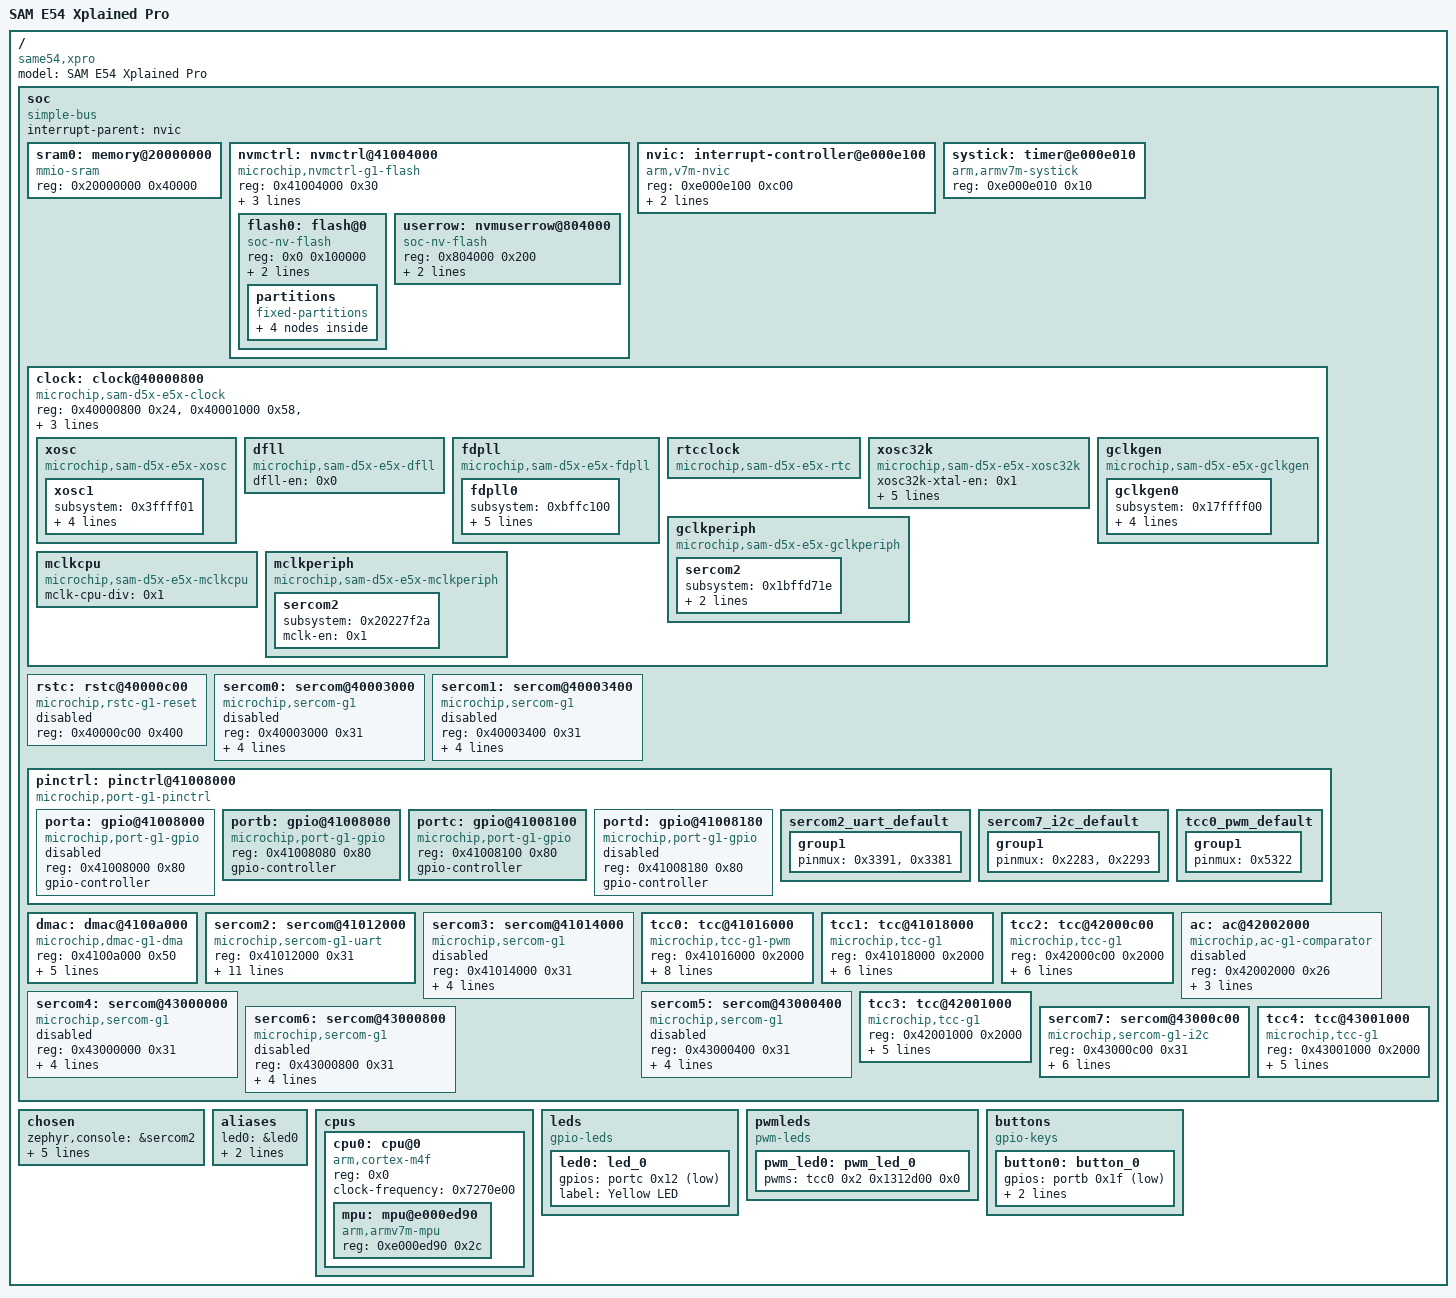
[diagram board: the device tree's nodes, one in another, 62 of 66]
/dts-v1/;

/* node '/' defined in zephyr/dts/arm/microchip/sam/sam_d5x_e5x/common/samd5xe5x_20.dtsi:7 */
/ {
	#address-cells = < 0x1 >;              /* in zephyr/dts/common/skeleton.dtsi:10 */
	#size-cells = < 0x1 >;                 /* in zephyr/dts/common/skeleton.dtsi:11 */
	model = "SAM E54 Xplained Pro";        /* in zephyr/boards/microchip/sam/sam_e54_xpro/sam_e54_xpro.dts:14 */
	compatible = "same54,xpro",
	             "microchip,atsame54p20a",
	             "microchip,same54";       /* in zephyr/boards/microchip/sam/sam_e54_xpro/sam_e54_xpro.dts:15 */

	/* node '/soc' defined in zephyr/dts/arm/microchip/sam/sam_d5x_e5x/common/samd5xe5x_20.dtsi:8 */
	soc {
		#address-cells = < 0x1 >;     /* in zephyr/dts/arm/armv7-m.dtsi:7 */
		#size-cells = < 0x1 >;        /* in zephyr/dts/arm/armv7-m.dtsi:8 */
		compatible = "simple-bus";    /* in zephyr/dts/arm/armv7-m.dtsi:9 */
		interrupt-parent = < &nvic >; /* in zephyr/dts/arm/armv7-m.dtsi:10 */
		ranges;                       /* in zephyr/dts/arm/armv7-m.dtsi:11 */

		/* node '/soc/memory@20000000' defined in zephyr/dts/arm/microchip/sam/sam_d5x_e5x/common/samd5xe5x_20.dtsi:9 */
		sram0: memory@20000000 {
			reg = < 0x20000000 0x40000 >; /* in zephyr/dts/arm/microchip/sam/sam_d5x_e5x/common/samd5xe5x_20.dtsi:10 */
			compatible = "mmio-sram";     /* in zephyr/dts/arm/microchip/sam/sam_d5x_e5x/common/samd5xe5x.dtsi:33 */
		};

		/* node '/soc/nvmctrl@41004000' defined in zephyr/dts/arm/microchip/sam/sam_d5x_e5x/common/samd5xe5x_20.dtsi:13 */
		nvmctrl: nvmctrl@41004000 {
			compatible = "microchip,nvmctrl-g1-flash"; /* in zephyr/dts/arm/microchip/sam/sam_d5x_e5x/common/samd5xe5x.dtsi:115 */
			status = "okay";                           /* in zephyr/dts/arm/microchip/sam/sam_d5x_e5x/common/samd5xe5x.dtsi:116 */
			reg = < 0x41004000 0x30 >;                 /* in zephyr/dts/arm/microchip/sam/sam_d5x_e5x/common/samd5xe5x.dtsi:117 */
			interrupts = < 0x1d 0x0 >,
			             < 0x1e 0x0 >;                 /* in zephyr/dts/arm/microchip/sam/sam_d5x_e5x/common/samd5xe5x.dtsi:118 */
			clocks = < &mclkperiph 0x2020bf27 >;       /* in zephyr/dts/arm/microchip/sam/sam_d5x_e5x/common/samd5xe5x.dtsi:119 */
			clock-names = "mclk";                      /* in zephyr/dts/arm/microchip/sam/sam_d5x_e5x/common/samd5xe5x.dtsi:120 */
			lock-regions = < 0x20 >;                   /* in zephyr/dts/arm/microchip/sam/sam_d5x_e5x/common/samd5xe5x.dtsi:121 */
			#address-cells = < 0x1 >;                  /* in zephyr/dts/arm/microchip/sam/sam_d5x_e5x/common/samd5xe5x.dtsi:122 */
			#size-cells = < 0x1 >;                     /* in zephyr/dts/arm/microchip/sam/sam_d5x_e5x/common/samd5xe5x.dtsi:123 */

			/* node '/soc/nvmctrl@41004000/flash@0' defined in zephyr/dts/arm/microchip/sam/sam_d5x_e5x/common/samd5xe5x_20.dtsi:14 */
			flash0: flash@0 {
				reg = < 0x0 0x100000 >;        /* in zephyr/dts/arm/microchip/sam/sam_d5x_e5x/common/samd5xe5x_20.dtsi:15 */
				compatible = "soc-nv-flash";   /* in zephyr/dts/arm/microchip/sam/sam_d5x_e5x/common/samd5xe5x.dtsi:126 */
				write-block-size = < 0x8 >;    /* in zephyr/dts/arm/microchip/sam/sam_d5x_e5x/common/samd5xe5x.dtsi:127 */
				erase-block-size = < 0x2000 >; /* in zephyr/dts/arm/microchip/sam/sam_d5x_e5x/common/samd5xe5x.dtsi:128 */

				/* node '/soc/nvmctrl@41004000/flash@0/partitions' defined in zephyr/boards/microchip/sam/sam_e54_xpro/sam_e54_xpro.dts:62 */
				partitions {
					compatible = "fixed-partitions"; /* in zephyr/boards/microchip/sam/sam_e54_xpro/sam_e54_xpro.dts:63 */
					#address-cells = < 0x1 >;        /* in zephyr/boards/microchip/sam/sam_e54_xpro/sam_e54_xpro.dts:64 */
					#size-cells = < 0x1 >;           /* in zephyr/boards/microchip/sam/sam_e54_xpro/sam_e54_xpro.dts:65 */

					/* node '/soc/nvmctrl@41004000/flash@0/partitions/partition@0' defined in zephyr/boards/microchip/sam/sam_e54_xpro/sam_e54_xpro.dts:67 */
					boot_partition: partition@0 {
						reg = < 0x0 0x10000 >; /* in zephyr/boards/microchip/sam/sam_e54_xpro/sam_e54_xpro.dts:68 */
						read-only;             /* in zephyr/boards/microchip/sam/sam_e54_xpro/sam_e54_xpro.dts:69 */
					};

					/* node '/soc/nvmctrl@41004000/flash@0/partitions/partition@10000' defined in zephyr/boards/microchip/sam/sam_e54_xpro/sam_e54_xpro.dts:72 */
					slot0_partition: partition@10000 {
						reg = < 0x10000 0x70000 >; /* in zephyr/boards/microchip/sam/sam_e54_xpro/sam_e54_xpro.dts:73 */
					};

					/* node '/soc/nvmctrl@41004000/flash@0/partitions/partition@80000' defined in zephyr/boards/microchip/sam/sam_e54_xpro/sam_e54_xpro.dts:76 */
					slot1_partition: partition@80000 {
						reg = < 0x80000 0x70000 >; /* in zephyr/boards/microchip/sam/sam_e54_xpro/sam_e54_xpro.dts:77 */
					};

					/* node '/soc/nvmctrl@41004000/flash@0/partitions/partition@f0000' defined in zephyr/boards/microchip/sam/sam_e54_xpro/sam_e54_xpro.dts:80 */
					storage_partition: partition@f0000 {
						reg = < 0xf0000 0x10000 >; /* in zephyr/boards/microchip/sam/sam_e54_xpro/sam_e54_xpro.dts:81 */
					};
				};
			};

			/* node '/soc/nvmctrl@41004000/nvmuserrow@804000' defined in zephyr/dts/arm/microchip/sam/sam_d5x_e5x/common/samd5xe5x.dtsi:131 */
			userrow: nvmuserrow@804000 {
				compatible = "soc-nv-flash";  /* in zephyr/dts/arm/microchip/sam/sam_d5x_e5x/common/samd5xe5x.dtsi:132 */
				reg = < 0x804000 0x200 >;     /* in zephyr/dts/arm/microchip/sam/sam_d5x_e5x/common/samd5xe5x.dtsi:133 */
				write-block-size = < 0x8 >;   /* in zephyr/dts/arm/microchip/sam/sam_d5x_e5x/common/samd5xe5x.dtsi:134 */
				erase-block-size = < 0x200 >; /* in zephyr/dts/arm/microchip/sam/sam_d5x_e5x/common/samd5xe5x.dtsi:135 */
			};
		};

		/* node '/soc/interrupt-controller@e000e100' defined in zephyr/dts/arm/armv7-m.dtsi:13 */
		nvic: interrupt-controller@e000e100 {
			#address-cells = < 0x1 >;            /* in zephyr/dts/arm/armv7-m.dtsi:14 */
			compatible = "arm,v7m-nvic";         /* in zephyr/dts/arm/armv7-m.dtsi:15 */
			reg = < 0xe000e100 0xc00 >;          /* in zephyr/dts/arm/armv7-m.dtsi:16 */
			interrupt-controller;                /* in zephyr/dts/arm/armv7-m.dtsi:17 */
			#interrupt-cells = < 0x2 >;          /* in zephyr/dts/arm/armv7-m.dtsi:18 */
			arm,num-irq-priority-bits = < 0x3 >; /* in zephyr/dts/arm/microchip/sam/sam_d5x_e5x/common/samd5xe5x.dtsi:261 */
			phandle = < 0x1 >;                   /* in zephyr/dts/arm/armv7-m.dtsi:10 */
		};

		/* node '/soc/timer@e000e010' defined in zephyr/dts/arm/armv7-m.dtsi:21 */
		systick: timer@e000e010 {
			compatible = "arm,armv7m-systick"; /* in zephyr/dts/arm/armv7-m.dtsi:22 */
			reg = < 0xe000e010 0x10 >;         /* in zephyr/dts/arm/armv7-m.dtsi:23 */
		};

		/* node '/soc/clock@40000800' defined in zephyr/dts/arm/microchip/sam/sam_d5x_e5x/common/samd5xe5x.dtsi:36 */
		clock: clock@40000800 {
			reg = < 0x40000800 0x24 >,
			      < 0x40001000 0x58 >,
			      < 0x40001400 0x20 >,
			      < 0x40001c00 0x140 >;                 /* in zephyr/dts/arm/microchip/sam/sam_d5x_e5x/common/samd5xe5x.dtsi:38 */
			reg-names = "mclk",
			            "oscctrl",
			            "osc32kctrl",
			            "gclk";                         /* in zephyr/dts/arm/microchip/sam/sam_d5x_e5x/common/samd5xe5x.dtsi:40 */
			interrupts = < 0x1 0x0 >,
			             < 0x2 0x0 >,
			             < 0x3 0x0 >,
			             < 0x4 0x0 >,
			             < 0x5 0x0 >,
			             < 0x6 0x0 >,
			             < 0x7 0x0 >;                   /* in zephyr/dts/arm/microchip/sam/sam_d5x_e5x/common/samd5xe5x.dtsi:42 */
			interrupt-names = "mclk",
			                  "xosc0",
			                  "xosc1",
			                  "dfll",
			                  "fdpll0",
			                  "fdpll1",
			                  "xosc32k";                /* in zephyr/dts/arm/microchip/sam/sam_d5x_e5x/common/samd5xe5x.dtsi:44 */
			compatible = "microchip,sam-d5x-e5x-clock"; /* in zephyr/boards/microchip/sam/sam_e54_xpro/sam_e54_xpro.dts:91 */

			/* node '/soc/clock@40000800/xosc' defined in zephyr/dts/arm/microchip/sam/sam_d5x_e5x/common/samd5xe5x.dtsi:47 */
			xosc: xosc {
				compatible = "microchip,sam-d5x-e5x-xosc"; /* in zephyr/boards/microchip/sam/sam_e54_xpro/sam_e54_xpro.dts:94 */

				/* node '/soc/clock@40000800/xosc/xosc1' defined in zephyr/boards/microchip/sam/sam_e54_xpro/sam_e54_xpro.dts:96 */
				xosc1 {
					subsystem = < 0x3ffff01 >;        /* in zephyr/boards/microchip/sam/sam_e54_xpro/sam_e54_xpro.dts:97 */
					xosc-frequency = < 0xb71b00 >;    /* in zephyr/boards/microchip/sam/sam_e54_xpro/sam_e54_xpro.dts:98 */
					xosc-en = < 0x1 >;                /* in zephyr/boards/microchip/sam/sam_e54_xpro/sam_e54_xpro.dts:99 */
					xosc-xtal-en = < 0x1 >;           /* in zephyr/boards/microchip/sam/sam_e54_xpro/sam_e54_xpro.dts:100 */
					xosc-run-in-standby-en = < 0x1 >; /* in zephyr/boards/microchip/sam/sam_e54_xpro/sam_e54_xpro.dts:101 */
				};
			};

			/* node '/soc/clock@40000800/dfll' defined in zephyr/dts/arm/microchip/sam/sam_d5x_e5x/common/samd5xe5x.dtsi:51 */
			dfll: dfll {
				compatible = "microchip,sam-d5x-e5x-dfll"; /* in zephyr/boards/microchip/sam/sam_e54_xpro/sam_e54_xpro.dts:106 */
				dfll-en = < 0x0 >;                         /* in zephyr/boards/microchip/sam/sam_e54_xpro/sam_e54_xpro.dts:107 */
			};

			/* node '/soc/clock@40000800/fdpll' defined in zephyr/dts/arm/microchip/sam/sam_d5x_e5x/common/samd5xe5x.dtsi:55 */
			fdpll: fdpll {
				compatible = "microchip,sam-d5x-e5x-fdpll"; /* in zephyr/boards/microchip/sam/sam_e54_xpro/sam_e54_xpro.dts:111 */

				/* node '/soc/clock@40000800/fdpll/fdpll0' defined in zephyr/boards/microchip/sam/sam_e54_xpro/sam_e54_xpro.dts:113 */
				fdpll0 {
					subsystem = < 0xbffc100 >;          /* in zephyr/boards/microchip/sam/sam_e54_xpro/sam_e54_xpro.dts:114 */
					fdpll-divider-ratio-int = < 0x13 >; /* in zephyr/boards/microchip/sam/sam_e54_xpro/sam_e54_xpro.dts:115 */
					fdpll-lock-bypass-en = < 0x1 >;     /* in zephyr/boards/microchip/sam/sam_e54_xpro/sam_e54_xpro.dts:116 */
					fdpll-wakeup-fast-en = < 0x1 >;     /* in zephyr/boards/microchip/sam/sam_e54_xpro/sam_e54_xpro.dts:117 */
					fdpll-src = "xosc1";                /* in zephyr/boards/microchip/sam/sam_e54_xpro/sam_e54_xpro.dts:118 */
					fdpll-en = < 0x1 >;                 /* in zephyr/boards/microchip/sam/sam_e54_xpro/sam_e54_xpro.dts:119 */
				};
			};

			/* node '/soc/clock@40000800/rtcclock' defined in zephyr/dts/arm/microchip/sam/sam_d5x_e5x/common/samd5xe5x.dtsi:59 */
			rtcclock: rtcclock {
				compatible = "microchip,sam-d5x-e5x-rtc"; /* in zephyr/dts/arm/microchip/sam/sam_d5x_e5x/common/samd5xe5x.dtsi:60 */
				#clock-cells = < 0x1 >;                   /* in zephyr/dts/arm/microchip/sam/sam_d5x_e5x/common/samd5xe5x.dtsi:61 */
			};

			/* node '/soc/clock@40000800/xosc32k' defined in zephyr/dts/arm/microchip/sam/sam_d5x_e5x/common/samd5xe5x.dtsi:64 */
			xosc32k: xosc32k {
				compatible = "microchip,sam-d5x-e5x-xosc32k"; /* in zephyr/boards/microchip/sam/sam_e54_xpro/sam_e54_xpro.dts:124 */
				xosc32k-xtal-en = < 0x1 >;                    /* in zephyr/boards/microchip/sam/sam_e54_xpro/sam_e54_xpro.dts:125 */
				xosc32k-startup-time = < 0x3e >;              /* in zephyr/boards/microchip/sam/sam_e54_xpro/sam_e54_xpro.dts:126 */
				xosc32k-gain-mode = "standard";               /* in zephyr/boards/microchip/sam/sam_e54_xpro/sam_e54_xpro.dts:127 */
				xosc32k-en = < 0x1 >;                         /* in zephyr/boards/microchip/sam/sam_e54_xpro/sam_e54_xpro.dts:128 */
				xosc32k-32khz-en = < 0x1 >;                   /* in zephyr/boards/microchip/sam/sam_e54_xpro/sam_e54_xpro.dts:129 */
				xosc32k-1khz-en = < 0x1 >;                    /* in zephyr/boards/microchip/sam/sam_e54_xpro/sam_e54_xpro.dts:130 */
			};

			/* node '/soc/clock@40000800/gclkgen' defined in zephyr/dts/arm/microchip/sam/sam_d5x_e5x/common/samd5xe5x.dtsi:68 */
			gclkgen: gclkgen {
				compatible = "microchip,sam-d5x-e5x-gclkgen"; /* in zephyr/boards/microchip/sam/sam_e54_xpro/sam_e54_xpro.dts:134 */

				/* node '/soc/clock@40000800/gclkgen/gclkgen0' defined in zephyr/boards/microchip/sam/sam_e54_xpro/sam_e54_xpro.dts:136 */
				gclkgen0 {
					subsystem = < 0x17ffff00 >;          /* in zephyr/boards/microchip/sam/sam_e54_xpro/sam_e54_xpro.dts:137 */
					gclkgen-div-factor = < 0x1 >;        /* in zephyr/boards/microchip/sam/sam_e54_xpro/sam_e54_xpro.dts:138 */
					gclkgen-run-in-standby-en = < 0x1 >; /* in zephyr/boards/microchip/sam/sam_e54_xpro/sam_e54_xpro.dts:139 */
					gclkgen-src = "fdpll0";              /* in zephyr/boards/microchip/sam/sam_e54_xpro/sam_e54_xpro.dts:140 */
					gclkgen-en = < 0x1 >;                /* in zephyr/boards/microchip/sam/sam_e54_xpro/sam_e54_xpro.dts:141 */
				};
			};

			/* node '/soc/clock@40000800/gclkperiph' defined in zephyr/dts/arm/microchip/sam/sam_d5x_e5x/common/samd5xe5x.dtsi:72 */
			gclkperiph: gclkperiph {
				compatible = "microchip,sam-d5x-e5x-gclkperiph"; /* in zephyr/boards/microchip/sam/sam_e54_xpro/sam_e54_xpro.dts:146 */
				#clock-cells = < 0x1 >;                          /* in zephyr/boards/microchip/sam/sam_e54_xpro/sam_e54_xpro.dts:147 */
				phandle = < 0x3 >;                               /* in zephyr/dts/arm/microchip/sam/sam_d5x_e5x/common/samd5xe5x.dtsi:99 */

				/* node '/soc/clock@40000800/gclkperiph/sercom2' defined in zephyr/boards/microchip/sam/sam_e54_xpro/sam_e54_xpro.dts:149 */
				sercom2 {
					subsystem = < 0x1bffd71e >; /* in zephyr/boards/microchip/sam/sam_e54_xpro/sam_e54_xpro.dts:150 */
					gclkperiph-src = "gclk0";   /* in zephyr/boards/microchip/sam/sam_e54_xpro/sam_e54_xpro.dts:151 */
					gclkperiph-en = < 0x1 >;    /* in zephyr/boards/microchip/sam/sam_e54_xpro/sam_e54_xpro.dts:152 */
				};
			};

			/* node '/soc/clock@40000800/mclkcpu' defined in zephyr/dts/arm/microchip/sam/sam_d5x_e5x/common/samd5xe5x.dtsi:77 */
			mclkcpu: mclkcpu {
				compatible = "microchip,sam-d5x-e5x-mclkcpu"; /* in zephyr/dts/arm/microchip/sam/sam_d5x_e5x/common/samd5xe5x.dtsi:78 */
				mclk-cpu-div = < 0x1 >;                       /* in zephyr/dts/arm/microchip/sam/sam_d5x_e5x/common/samd5xe5x.dtsi:79 */
			};

			/* node '/soc/clock@40000800/mclkperiph' defined in zephyr/dts/arm/microchip/sam/sam_d5x_e5x/common/samd5xe5x.dtsi:82 */
			mclkperiph: mclkperiph {
				compatible = "microchip,sam-d5x-e5x-mclkperiph"; /* in zephyr/boards/microchip/sam/sam_e54_xpro/sam_e54_xpro.dts:157 */
				#clock-cells = < 0x1 >;                          /* in zephyr/boards/microchip/sam/sam_e54_xpro/sam_e54_xpro.dts:158 */
				phandle = < 0x2 >;                               /* in zephyr/dts/arm/microchip/sam/sam_d5x_e5x/common/samd5xe5x.dtsi:119 */

				/* node '/soc/clock@40000800/mclkperiph/sercom2' defined in zephyr/boards/microchip/sam/sam_e54_xpro/sam_e54_xpro.dts:160 */
				sercom2 {
					subsystem = < 0x20227f2a >; /* in zephyr/boards/microchip/sam/sam_e54_xpro/sam_e54_xpro.dts:161 */
					mclk-en = < 0x1 >;          /* in zephyr/boards/microchip/sam/sam_e54_xpro/sam_e54_xpro.dts:162 */
				};
			};
		};

		/* node '/soc/rstc@40000c00' defined in zephyr/dts/arm/microchip/sam/sam_d5x_e5x/common/samd5xe5x.dtsi:88 */
		rstc: rstc@40000c00 {
			compatible = "microchip,rstc-g1-reset"; /* in zephyr/dts/arm/microchip/sam/sam_d5x_e5x/common/samd5xe5x.dtsi:89 */
			status = "disabled";                    /* in zephyr/dts/arm/microchip/sam/sam_d5x_e5x/common/samd5xe5x.dtsi:90 */
			reg = < 0x40000c00 0x400 >;             /* in zephyr/dts/arm/microchip/sam/sam_d5x_e5x/common/samd5xe5x.dtsi:91 */
		};

		/* node '/soc/sercom@40003000' defined in zephyr/dts/arm/microchip/sam/sam_d5x_e5x/common/samd5xe5x.dtsi:94 */
		sercom0: sercom@40003000 {
			compatible = "microchip,sercom-g1";  /* in zephyr/dts/arm/microchip/sam/sam_d5x_e5x/common/samd5xe5x.dtsi:95 */
			status = "disabled";                 /* in zephyr/dts/arm/microchip/sam/sam_d5x_e5x/common/samd5xe5x.dtsi:96 */
			reg = < 0x40003000 0x31 >;           /* in zephyr/dts/arm/microchip/sam/sam_d5x_e5x/common/samd5xe5x.dtsi:97 */
			interrupts = < 0x2e 0x0 >,
			             < 0x2f 0x0 >,
			             < 0x30 0x0 >,
			             < 0x31 0x0 >;           /* in zephyr/dts/arm/microchip/sam/sam_d5x_e5x/common/samd5xe5x.dtsi:98 */
			clocks = < &mclkperiph 0x20133f21 >,
			         < &gclkperiph 0x1bffc70d >; /* in zephyr/dts/arm/microchip/sam/sam_d5x_e5x/common/samd5xe5x.dtsi:99 */
			clock-names = "mclk",
			              "gclk";                /* in zephyr/dts/arm/microchip/sam/sam_d5x_e5x/common/samd5xe5x.dtsi:101 */
		};

		/* node '/soc/sercom@40003400' defined in zephyr/dts/arm/microchip/sam/sam_d5x_e5x/common/samd5xe5x.dtsi:104 */
		sercom1: sercom@40003400 {
			compatible = "microchip,sercom-g1";  /* in zephyr/dts/arm/microchip/sam/sam_d5x_e5x/common/samd5xe5x.dtsi:105 */
			status = "disabled";                 /* in zephyr/dts/arm/microchip/sam/sam_d5x_e5x/common/samd5xe5x.dtsi:106 */
			reg = < 0x40003400 0x31 >;           /* in zephyr/dts/arm/microchip/sam/sam_d5x_e5x/common/samd5xe5x.dtsi:107 */
			interrupts = < 0x32 0x0 >,
			             < 0x33 0x0 >,
			             < 0x34 0x0 >,
			             < 0x35 0x0 >;           /* in zephyr/dts/arm/microchip/sam/sam_d5x_e5x/common/samd5xe5x.dtsi:108 */
			clocks = < &mclkperiph 0x20137f22 >,
			         < &gclkperiph 0x1bffc80e >; /* in zephyr/dts/arm/microchip/sam/sam_d5x_e5x/common/samd5xe5x.dtsi:109 */
			clock-names = "mclk",
			              "gclk";                /* in zephyr/dts/arm/microchip/sam/sam_d5x_e5x/common/samd5xe5x.dtsi:111 */
		};

		/* node '/soc/pinctrl@41008000' defined in zephyr/dts/arm/microchip/sam/sam_d5x_e5x/common/samd5xe5x.dtsi:139 */
		pinctrl: pinctrl@41008000 {
			compatible = "microchip,port-g1-pinctrl"; /* in zephyr/dts/arm/microchip/sam/sam_d5x_e5x/common/samd5xe5x.dtsi:140 */
			#address-cells = < 0x1 >;                 /* in zephyr/dts/arm/microchip/sam/sam_d5x_e5x/common/samd5xe5x.dtsi:141 */
			#size-cells = < 0x1 >;                    /* in zephyr/dts/arm/microchip/sam/sam_d5x_e5x/common/samd5xe5x.dtsi:142 */
			ranges = < 0x41008000 0x41008000 0x200 >; /* in zephyr/dts/arm/microchip/sam/sam_d5x_e5x/common/samd5xe5x.dtsi:143 */

			/* node '/soc/pinctrl@41008000/gpio@41008000' defined in zephyr/dts/arm/microchip/sam/sam_d5x_e5x/common/samd5xe5x.dtsi:145 */
			porta: gpio@41008000 {
				compatible = "microchip,port-g1-gpio"; /* in zephyr/dts/arm/microchip/sam/sam_d5x_e5x/common/samd5xe5x.dtsi:146 */
				reg = < 0x41008000 0x80 >;             /* in zephyr/dts/arm/microchip/sam/sam_d5x_e5x/common/samd5xe5x.dtsi:147 */
				gpio-controller;                       /* in zephyr/dts/arm/microchip/sam/sam_d5x_e5x/common/samd5xe5x.dtsi:148 */
				#gpio-cells = < 0x2 >;                 /* in zephyr/dts/arm/microchip/sam/sam_d5x_e5x/common/samd5xe5x.dtsi:149 */
				#microchip,pin-cells = < 0x2 >;        /* in zephyr/dts/arm/microchip/sam/sam_d5x_e5x/common/samd5xe5x.dtsi:150 */
				status = "disabled";                   /* in zephyr/dts/arm/microchip/sam/sam_d5x_e5x/common/samd5xe5x.dtsi:151 */
			};

			/* node '/soc/pinctrl@41008000/gpio@41008080' defined in zephyr/dts/arm/microchip/sam/sam_d5x_e5x/common/samd5xe5x.dtsi:154 */
			portb: gpio@41008080 {
				compatible = "microchip,port-g1-gpio"; /* in zephyr/dts/arm/microchip/sam/sam_d5x_e5x/common/samd5xe5x.dtsi:155 */
				reg = < 0x41008080 0x80 >;             /* in zephyr/dts/arm/microchip/sam/sam_d5x_e5x/common/samd5xe5x.dtsi:156 */
				gpio-controller;                       /* in zephyr/dts/arm/microchip/sam/sam_d5x_e5x/common/samd5xe5x.dtsi:157 */
				#gpio-cells = < 0x2 >;                 /* in zephyr/dts/arm/microchip/sam/sam_d5x_e5x/common/samd5xe5x.dtsi:158 */
				#microchip,pin-cells = < 0x2 >;        /* in zephyr/dts/arm/microchip/sam/sam_d5x_e5x/common/samd5xe5x.dtsi:159 */
				status = "okay";                       /* in zephyr/boards/microchip/sam/sam_e54_xpro/sam_e54_xpro.dts:207 */
				phandle = < 0x9 >;                     /* in zephyr/boards/microchip/sam/sam_e54_xpro/sam_e54_xpro.dts:54 */
			};

			/* node '/soc/pinctrl@41008000/gpio@41008100' defined in zephyr/dts/arm/microchip/sam/sam_d5x_e5x/common/samd5xe5x_p.dtsi:57 */
			portc: gpio@41008100 {
				compatible = "microchip,port-g1-gpio"; /* in zephyr/dts/arm/microchip/sam/sam_d5x_e5x/common/samd5xe5x_p.dtsi:58 */
				reg = < 0x41008100 0x80 >;             /* in zephyr/dts/arm/microchip/sam/sam_d5x_e5x/common/samd5xe5x_p.dtsi:59 */
				gpio-controller;                       /* in zephyr/dts/arm/microchip/sam/sam_d5x_e5x/common/samd5xe5x_p.dtsi:60 */
				#gpio-cells = < 0x2 >;                 /* in zephyr/dts/arm/microchip/sam/sam_d5x_e5x/common/samd5xe5x_p.dtsi:61 */
				#microchip,pin-cells = < 0x2 >;        /* in zephyr/dts/arm/microchip/sam/sam_d5x_e5x/common/samd5xe5x_p.dtsi:62 */
				status = "okay";                       /* in zephyr/boards/microchip/sam/sam_e54_xpro/sam_e54_xpro.dts:211 */
				phandle = < 0x7 >;                     /* in zephyr/boards/microchip/sam/sam_e54_xpro/sam_e54_xpro.dts:36 */
			};

			/* node '/soc/pinctrl@41008000/gpio@41008180' defined in zephyr/dts/arm/microchip/sam/sam_d5x_e5x/common/samd5xe5x_p.dtsi:66 */
			portd: gpio@41008180 {
				compatible = "microchip,port-g1-gpio"; /* in zephyr/dts/arm/microchip/sam/sam_d5x_e5x/common/samd5xe5x_p.dtsi:67 */
				reg = < 0x41008180 0x80 >;             /* in zephyr/dts/arm/microchip/sam/sam_d5x_e5x/common/samd5xe5x_p.dtsi:68 */
				gpio-controller;                       /* in zephyr/dts/arm/microchip/sam/sam_d5x_e5x/common/samd5xe5x_p.dtsi:69 */
				#gpio-cells = < 0x2 >;                 /* in zephyr/dts/arm/microchip/sam/sam_d5x_e5x/common/samd5xe5x_p.dtsi:70 */
				#microchip,pin-cells = < 0x2 >;        /* in zephyr/dts/arm/microchip/sam/sam_d5x_e5x/common/samd5xe5x_p.dtsi:71 */
				status = "disabled";                   /* in zephyr/dts/arm/microchip/sam/sam_d5x_e5x/common/samd5xe5x_p.dtsi:72 */
			};

			/* node '/soc/pinctrl@41008000/sercom2_uart_default' defined in zephyr/boards/microchip/sam/sam_e54_xpro/sam_e54_xpro-pinctrl.dtsi:10 */
			sercom2_uart_default: sercom2_uart_default {
				phandle = < 0x4 >; /* in zephyr/boards/microchip/sam/sam_e54_xpro/sam_e54_xpro.dts:181 */

				/* node '/soc/pinctrl@41008000/sercom2_uart_default/group1' defined in zephyr/boards/microchip/sam/sam_e54_xpro/sam_e54_xpro-pinctrl.dtsi:11 */
				group1 {
					pinmux = < 0x3391 >,
					         < 0x3381 >; /* in zephyr/boards/microchip/sam/sam_e54_xpro/sam_e54_xpro-pinctrl.dtsi:12 */
				};
			};

			/* node '/soc/pinctrl@41008000/sercom7_i2c_default' defined in zephyr/boards/microchip/sam/sam_e54_xpro/sam_e54_xpro-pinctrl.dtsi:17 */
			sercom7_i2c_default: sercom7_i2c_default {
				phandle = < 0x6 >; /* in zephyr/boards/microchip/sam/sam_e54_xpro/sam_e54_xpro.dts:190 */

				/* node '/soc/pinctrl@41008000/sercom7_i2c_default/group1' defined in zephyr/boards/microchip/sam/sam_e54_xpro/sam_e54_xpro-pinctrl.dtsi:18 */
				group1 {
					pinmux = < 0x2283 >,
					         < 0x2293 >; /* in zephyr/boards/microchip/sam/sam_e54_xpro/sam_e54_xpro-pinctrl.dtsi:19 */
				};
			};

			/* node '/soc/pinctrl@41008000/tcc0_pwm_default' defined in zephyr/boards/microchip/sam/sam_e54_xpro/sam_e54_xpro-pinctrl.dtsi:24 */
			tcc0_pwm_default: tcc0_pwm_default {
				phandle = < 0x5 >; /* in zephyr/boards/microchip/sam/sam_e54_xpro/sam_e54_xpro.dts:199 */

				/* node '/soc/pinctrl@41008000/tcc0_pwm_default/group1' defined in zephyr/boards/microchip/sam/sam_e54_xpro/sam_e54_xpro-pinctrl.dtsi:25 */
				group1 {
					pinmux = < 0x5322 >; /* in zephyr/boards/microchip/sam/sam_e54_xpro/sam_e54_xpro-pinctrl.dtsi:26 */
				};
			};
		};

		/* node '/soc/dmac@4100a000' defined in zephyr/dts/arm/microchip/sam/sam_d5x_e5x/common/samd5xe5x.dtsi:164 */
		dmac: dmac@4100a000 {
			compatible = "microchip,dmac-g1-dma"; /* in zephyr/dts/arm/microchip/sam/sam_d5x_e5x/common/samd5xe5x.dtsi:165 */
			reg = < 0x4100a000 0x50 >;            /* in zephyr/dts/arm/microchip/sam/sam_d5x_e5x/common/samd5xe5x.dtsi:166 */
			interrupts = < 0x1f 0x0 >,
			             < 0x20 0x0 >,
			             < 0x21 0x0 >,
			             < 0x22 0x0 >,
			             < 0x23 0x0 >;            /* in zephyr/dts/arm/microchip/sam/sam_d5x_e5x/common/samd5xe5x.dtsi:167 */
			clocks = < &mclkperiph 0x20027f07 >;  /* in zephyr/dts/arm/microchip/sam/sam_d5x_e5x/common/samd5xe5x.dtsi:168 */
			clock-names = "mclk";                 /* in zephyr/dts/arm/microchip/sam/sam_d5x_e5x/common/samd5xe5x.dtsi:169 */
			dma-channels = < 0x20 >;              /* in zephyr/dts/arm/microchip/sam/sam_d5x_e5x/common/samd5xe5x.dtsi:170 */
			dma-alignment = < 0x10 >;             /* in zephyr/dts/arm/microchip/sam/sam_d5x_e5x/common/samd5xe5x.dtsi:171 */
			#dma-cells = < 0x2 >;                 /* in zephyr/dts/arm/microchip/sam/sam_d5x_e5x/common/samd5xe5x.dtsi:172 */
		};

		/* node '/soc/sercom@41012000' defined in zephyr/dts/arm/microchip/sam/sam_d5x_e5x/common/samd5xe5x.dtsi:175 */
		sercom2: sercom@41012000 {
			reg = < 0x41012000 0x31 >;               /* in zephyr/dts/arm/microchip/sam/sam_d5x_e5x/common/samd5xe5x.dtsi:178 */
			interrupts = < 0x36 0x0 >,
			             < 0x37 0x0 >,
			             < 0x38 0x0 >,
			             < 0x39 0x0 >;               /* in zephyr/dts/arm/microchip/sam/sam_d5x_e5x/common/samd5xe5x.dtsi:179 */
			clocks = < &mclkperiph 0x20227f2a >,
			         < &gclkperiph 0x1bffd71e >;     /* in zephyr/dts/arm/microchip/sam/sam_d5x_e5x/common/samd5xe5x.dtsi:180 */
			clock-names = "mclk",
			              "gclk";                    /* in zephyr/dts/arm/microchip/sam/sam_d5x_e5x/common/samd5xe5x.dtsi:182 */
			status = "okay";                         /* in zephyr/boards/microchip/sam/sam_e54_xpro/sam_e54_xpro.dts:168 */
			compatible = "microchip,sercom-g1-uart"; /* in zephyr/boards/microchip/sam/sam_e54_xpro/sam_e54_xpro.dts:169 */
			#address-cells = < 0x1 >;                /* in zephyr/boards/microchip/sam/sam_e54_xpro/sam_e54_xpro.dts:170 */
			#size-cells = < 0x0 >;                   /* in zephyr/boards/microchip/sam/sam_e54_xpro/sam_e54_xpro.dts:171 */
			current-speed = < 0x1c200 >;             /* in zephyr/boards/microchip/sam/sam_e54_xpro/sam_e54_xpro.dts:173 */
			data-bits = < 0x8 >;                     /* in zephyr/boards/microchip/sam/sam_e54_xpro/sam_e54_xpro.dts:174 */
			parity = "none";                         /* in zephyr/boards/microchip/sam/sam_e54_xpro/sam_e54_xpro.dts:175 */
			stop-bits = "1";                         /* in zephyr/boards/microchip/sam/sam_e54_xpro/sam_e54_xpro.dts:176 */
			rxpo = < 0x1 >;                          /* in zephyr/boards/microchip/sam/sam_e54_xpro/sam_e54_xpro.dts:178 */
			txpo = < 0x0 >;                          /* in zephyr/boards/microchip/sam/sam_e54_xpro/sam_e54_xpro.dts:179 */
			pinctrl-0 = < &sercom2_uart_default >;   /* in zephyr/boards/microchip/sam/sam_e54_xpro/sam_e54_xpro.dts:181 */
			pinctrl-names = "default";               /* in zephyr/boards/microchip/sam/sam_e54_xpro/sam_e54_xpro.dts:182 */
		};

		/* node '/soc/sercom@41014000' defined in zephyr/dts/arm/microchip/sam/sam_d5x_e5x/common/samd5xe5x.dtsi:185 */
		sercom3: sercom@41014000 {
			compatible = "microchip,sercom-g1";  /* in zephyr/dts/arm/microchip/sam/sam_d5x_e5x/common/samd5xe5x.dtsi:186 */
			status = "disabled";                 /* in zephyr/dts/arm/microchip/sam/sam_d5x_e5x/common/samd5xe5x.dtsi:187 */
			reg = < 0x41014000 0x31 >;           /* in zephyr/dts/arm/microchip/sam/sam_d5x_e5x/common/samd5xe5x.dtsi:188 */
			interrupts = < 0x3a 0x0 >,
			             < 0x3b 0x0 >,
			             < 0x3c 0x0 >,
			             < 0x3d 0x0 >;           /* in zephyr/dts/arm/microchip/sam/sam_d5x_e5x/common/samd5xe5x.dtsi:189 */
			clocks = < &mclkperiph 0x2022bf2b >,
			         < &gclkperiph 0x1bffd81f >; /* in zephyr/dts/arm/microchip/sam/sam_d5x_e5x/common/samd5xe5x.dtsi:190 */
			clock-names = "mclk",
			              "gclk";                /* in zephyr/dts/arm/microchip/sam/sam_d5x_e5x/common/samd5xe5x.dtsi:192 */
		};

		/* node '/soc/tcc@41016000' defined in zephyr/dts/arm/microchip/sam/sam_d5x_e5x/common/samd5xe5x.dtsi:195 */
		tcc0: tcc@41016000 {
			reg = < 0x41016000 0x2000 >;         /* in zephyr/dts/arm/microchip/sam/sam_d5x_e5x/common/samd5xe5x.dtsi:197 */
			interrupts = < 0x55 0x0 >,
			             < 0x56 0x0 >,
			             < 0x57 0x0 >,
			             < 0x58 0x0 >,
			             < 0x59 0x0 >,
			             < 0x5a 0x0 >,
			             < 0x5b 0x0 >;           /* in zephyr/dts/arm/microchip/sam/sam_d5x_e5x/common/samd5xe5x.dtsi:198 */
			clocks = < &mclkperiph 0x2022ff2c >,
			         < &gclkperiph 0x1bffd920 >; /* in zephyr/dts/arm/microchip/sam/sam_d5x_e5x/common/samd5xe5x.dtsi:199 */
			clock-names = "mclk",
			              "gclk";                /* in zephyr/dts/arm/microchip/sam/sam_d5x_e5x/common/samd5xe5x.dtsi:201 */
			compatible = "microchip,tcc-g1-pwm"; /* in zephyr/boards/microchip/sam/sam_e54_xpro/sam_e54_xpro.dts:196 */
			status = "okay";                     /* in zephyr/boards/microchip/sam/sam_e54_xpro/sam_e54_xpro.dts:197 */
			#pwm-cells = < 0x3 >;                /* in zephyr/boards/microchip/sam/sam_e54_xpro/sam_e54_xpro.dts:198 */
			pinctrl-0 = < &tcc0_pwm_default >;   /* in zephyr/boards/microchip/sam/sam_e54_xpro/sam_e54_xpro.dts:199 */
			pinctrl-names = "default";           /* in zephyr/boards/microchip/sam/sam_e54_xpro/sam_e54_xpro.dts:200 */
			max-bit-width = < 0x18 >;            /* in zephyr/boards/microchip/sam/sam_e54_xpro/sam_e54_xpro.dts:201 */
			prescaler = < 0x8 >;                 /* in zephyr/boards/microchip/sam/sam_e54_xpro/sam_e54_xpro.dts:202 */
			channels = < 0x6 >;                  /* in zephyr/boards/microchip/sam/sam_e54_xpro/sam_e54_xpro.dts:203 */
			phandle = < 0x8 >;                   /* in zephyr/boards/microchip/sam/sam_e54_xpro/sam_e54_xpro.dts:46 */
		};

		/* node '/soc/tcc@41018000' defined in zephyr/dts/arm/microchip/sam/sam_d5x_e5x/common/samd5xe5x.dtsi:206 */
		tcc1: tcc@41018000 {
			compatible = "microchip,tcc-g1";     /* in zephyr/dts/arm/microchip/sam/sam_d5x_e5x/common/samd5xe5x.dtsi:207 */
			reg = < 0x41018000 0x2000 >;         /* in zephyr/dts/arm/microchip/sam/sam_d5x_e5x/common/samd5xe5x.dtsi:208 */
			interrupts = < 0x5c 0x0 >,
			             < 0x5d 0x0 >,
			             < 0x5e 0x0 >,
			             < 0x5f 0x0 >,
			             < 0x60 0x0 >;           /* in zephyr/dts/arm/microchip/sam/sam_d5x_e5x/common/samd5xe5x.dtsi:209 */
			clocks = < &mclkperiph 0x20233f2d >,
			         < &gclkperiph 0x1bffd921 >; /* in zephyr/dts/arm/microchip/sam/sam_d5x_e5x/common/samd5xe5x.dtsi:210 */
			clock-names = "mclk",
			              "gclk";                /* in zephyr/dts/arm/microchip/sam/sam_d5x_e5x/common/samd5xe5x.dtsi:212 */
			max-bit-width = < 0x18 >;            /* in zephyr/dts/arm/microchip/sam/sam_d5x_e5x/common/samd5xe5x.dtsi:213 */
			channels = < 0x4 >;                  /* in zephyr/dts/arm/microchip/sam/sam_d5x_e5x/common/samd5xe5x.dtsi:214 */
		};

		/* node '/soc/tcc@42000c00' defined in zephyr/dts/arm/microchip/sam/sam_d5x_e5x/common/samd5xe5x.dtsi:217 */
		tcc2: tcc@42000c00 {
			compatible = "microchip,tcc-g1";     /* in zephyr/dts/arm/microchip/sam/sam_d5x_e5x/common/samd5xe5x.dtsi:218 */
			reg = < 0x42000c00 0x2000 >;         /* in zephyr/dts/arm/microchip/sam/sam_d5x_e5x/common/samd5xe5x.dtsi:219 */
			interrupts = < 0x61 0x0 >,
			             < 0x62 0x0 >,
			             < 0x63 0x0 >,
			             < 0x64 0x0 >;           /* in zephyr/dts/arm/microchip/sam/sam_d5x_e5x/common/samd5xe5x.dtsi:220 */
			clocks = < &mclkperiph 0x2030ff32 >,
			         < &gclkperiph 0x1bffdd26 >; /* in zephyr/dts/arm/microchip/sam/sam_d5x_e5x/common/samd5xe5x.dtsi:221 */
			clock-names = "mclk",
			              "gclk";                /* in zephyr/dts/arm/microchip/sam/sam_d5x_e5x/common/samd5xe5x.dtsi:223 */
			max-bit-width = < 0x10 >;            /* in zephyr/dts/arm/microchip/sam/sam_d5x_e5x/common/samd5xe5x.dtsi:224 */
			channels = < 0x3 >;                  /* in zephyr/dts/arm/microchip/sam/sam_d5x_e5x/common/samd5xe5x.dtsi:225 */
		};

		/* node '/soc/ac@42002000' defined in zephyr/dts/arm/microchip/sam/sam_d5x_e5x/common/samd5xe5x.dtsi:228 */
		ac: ac@42002000 {
			compatible = "microchip,ac-g1-comparator"; /* in zephyr/dts/arm/microchip/sam/sam_d5x_e5x/common/samd5xe5x.dtsi:229 */
			status = "disabled";                       /* in zephyr/dts/arm/microchip/sam/sam_d5x_e5x/common/samd5xe5x.dtsi:230 */
			reg = < 0x42002000 0x26 >;                 /* in zephyr/dts/arm/microchip/sam/sam_d5x_e5x/common/samd5xe5x.dtsi:231 */
			interrupts = < 0x7a 0x0 >;                 /* in zephyr/dts/arm/microchip/sam/sam_d5x_e5x/common/samd5xe5x.dtsi:232 */
			clocks = < &mclkperiph 0x20323f37 >,
			         < &gclkperiph 0x1bffe02b >;       /* in zephyr/dts/arm/microchip/sam/sam_d5x_e5x/common/samd5xe5x.dtsi:233 */
			clock-names = "mclk",
			              "gclk";                      /* in zephyr/dts/arm/microchip/sam/sam_d5x_e5x/common/samd5xe5x.dtsi:235 */
		};

		/* node '/soc/sercom@43000000' defined in zephyr/dts/arm/microchip/sam/sam_d5x_e5x/common/samd5xe5x.dtsi:238 */
		sercom4: sercom@43000000 {
			compatible = "microchip,sercom-g1";  /* in zephyr/dts/arm/microchip/sam/sam_d5x_e5x/common/samd5xe5x.dtsi:239 */
			status = "disabled";                 /* in zephyr/dts/arm/microchip/sam/sam_d5x_e5x/common/samd5xe5x.dtsi:240 */
			reg = < 0x43000000 0x31 >;           /* in zephyr/dts/arm/microchip/sam/sam_d5x_e5x/common/samd5xe5x.dtsi:241 */
			interrupts = < 0x3e 0x0 >,
			             < 0x3f 0x0 >,
			             < 0x40 0x0 >,
			             < 0x41 0x0 >;           /* in zephyr/dts/arm/microchip/sam/sam_d5x_e5x/common/samd5xe5x.dtsi:242 */
			clocks = < &mclkperiph 0x20403f3d >,
			         < &gclkperiph 0x1bffe22d >; /* in zephyr/dts/arm/microchip/sam/sam_d5x_e5x/common/samd5xe5x.dtsi:243 */
			clock-names = "mclk",
			              "gclk";                /* in zephyr/dts/arm/microchip/sam/sam_d5x_e5x/common/samd5xe5x.dtsi:245 */
		};

		/* node '/soc/sercom@43000400' defined in zephyr/dts/arm/microchip/sam/sam_d5x_e5x/common/samd5xe5x.dtsi:248 */
		sercom5: sercom@43000400 {
			compatible = "microchip,sercom-g1";  /* in zephyr/dts/arm/microchip/sam/sam_d5x_e5x/common/samd5xe5x.dtsi:249 */
			status = "disabled";                 /* in zephyr/dts/arm/microchip/sam/sam_d5x_e5x/common/samd5xe5x.dtsi:250 */
			reg = < 0x43000400 0x31 >;           /* in zephyr/dts/arm/microchip/sam/sam_d5x_e5x/common/samd5xe5x.dtsi:251 */
			interrupts = < 0x42 0x0 >,
			             < 0x43 0x0 >,
			             < 0x44 0x0 >,
			             < 0x45 0x0 >;           /* in zephyr/dts/arm/microchip/sam/sam_d5x_e5x/common/samd5xe5x.dtsi:252 */
			clocks = < &mclkperiph 0x20407f3e >,
			         < &gclkperiph 0x1bffe32e >; /* in zephyr/dts/arm/microchip/sam/sam_d5x_e5x/common/samd5xe5x.dtsi:253 */
			clock-names = "mclk",
			              "gclk";                /* in zephyr/dts/arm/microchip/sam/sam_d5x_e5x/common/samd5xe5x.dtsi:255 */
		};

		/* node '/soc/tcc@42001000' defined in zephyr/dts/arm/microchip/sam/sam_d5x_e5x/common/samd5xe5x_p.dtsi:11 */
		tcc3: tcc@42001000 {
			compatible = "microchip,tcc-g1";     /* in zephyr/dts/arm/microchip/sam/sam_d5x_e5x/common/samd5xe5x_p.dtsi:12 */
			reg = < 0x42001000 0x2000 >;         /* in zephyr/dts/arm/microchip/sam/sam_d5x_e5x/common/samd5xe5x_p.dtsi:13 */
			interrupts = < 0x65 0x0 >,
			             < 0x66 0x0 >,
			             < 0x67 0x0 >;           /* in zephyr/dts/arm/microchip/sam/sam_d5x_e5x/common/samd5xe5x_p.dtsi:14 */
			clocks = < &mclkperiph 0x20313f33 >,
			         < &gclkperiph 0x1bffdd27 >; /* in zephyr/dts/arm/microchip/sam/sam_d5x_e5x/common/samd5xe5x_p.dtsi:15 */
			clock-names = "mclk",
			              "gclk";                /* in zephyr/dts/arm/microchip/sam/sam_d5x_e5x/common/samd5xe5x_p.dtsi:17 */
			max-bit-width = < 0x10 >;            /* in zephyr/dts/arm/microchip/sam/sam_d5x_e5x/common/samd5xe5x_p.dtsi:18 */
			channels = < 0x2 >;                  /* in zephyr/dts/arm/microchip/sam/sam_d5x_e5x/common/samd5xe5x_p.dtsi:19 */
		};

		/* node '/soc/sercom@43000800' defined in zephyr/dts/arm/microchip/sam/sam_d5x_e5x/common/samd5xe5x_p.dtsi:22 */
		sercom6: sercom@43000800 {
			compatible = "microchip,sercom-g1";  /* in zephyr/dts/arm/microchip/sam/sam_d5x_e5x/common/samd5xe5x_p.dtsi:23 */
			status = "disabled";                 /* in zephyr/dts/arm/microchip/sam/sam_d5x_e5x/common/samd5xe5x_p.dtsi:24 */
			reg = < 0x43000800 0x31 >;           /* in zephyr/dts/arm/microchip/sam/sam_d5x_e5x/common/samd5xe5x_p.dtsi:25 */
			interrupts = < 0x46 0x0 >,
			             < 0x47 0x0 >,
			             < 0x48 0x0 >,
			             < 0x49 0x0 >;           /* in zephyr/dts/arm/microchip/sam/sam_d5x_e5x/common/samd5xe5x_p.dtsi:26 */
			clocks = < &mclkperiph 0x2040bf3f >,
			         < &gclkperiph 0x1bffe42f >; /* in zephyr/dts/arm/microchip/sam/sam_d5x_e5x/common/samd5xe5x_p.dtsi:27 */
			clock-names = "mclk",
			              "gclk";                /* in zephyr/dts/arm/microchip/sam/sam_d5x_e5x/common/samd5xe5x_p.dtsi:29 */
		};

		/* node '/soc/sercom@43000c00' defined in zephyr/dts/arm/microchip/sam/sam_d5x_e5x/common/samd5xe5x_p.dtsi:32 */
		sercom7: sercom@43000c00 {
			reg = < 0x43000c00 0x31 >;              /* in zephyr/dts/arm/microchip/sam/sam_d5x_e5x/common/samd5xe5x_p.dtsi:34 */
			interrupts = < 0x4a 0x0 >,
			             < 0x4b 0x0 >,
			             < 0x4c 0x0 >,
			             < 0x4d 0x0 >;              /* in zephyr/dts/arm/microchip/sam/sam_d5x_e5x/common/samd5xe5x_p.dtsi:35 */
			interrupt-names = "source-0",
			                  "source-1",
			                  "source-2",
			                  "source-3-7";         /* in zephyr/dts/arm/microchip/sam/sam_d5x_e5x/common/samd5xe5x_p.dtsi:36 */
			clocks = < &mclkperiph 0x2040ff40 >,
			         < &gclkperiph 0x1bffe530 >;    /* in zephyr/dts/arm/microchip/sam/sam_d5x_e5x/common/samd5xe5x_p.dtsi:37 */
			clock-names = "mclk",
			              "gclk";                   /* in zephyr/dts/arm/microchip/sam/sam_d5x_e5x/common/samd5xe5x_p.dtsi:39 */
			compatible = "microchip,sercom-g1-i2c"; /* in zephyr/boards/microchip/sam/sam_e54_xpro/sam_e54_xpro.dts:186 */
			#address-cells = < 0x1 >;               /* in zephyr/boards/microchip/sam/sam_e54_xpro/sam_e54_xpro.dts:187 */
			#size-cells = < 0x0 >;                  /* in zephyr/boards/microchip/sam/sam_e54_xpro/sam_e54_xpro.dts:188 */
			clock-frequency = < 0x61a80 >;          /* in zephyr/boards/microchip/sam/sam_e54_xpro/sam_e54_xpro.dts:189 */
			pinctrl-0 = < &sercom7_i2c_default >;   /* in zephyr/boards/microchip/sam/sam_e54_xpro/sam_e54_xpro.dts:190 */
			pinctrl-names = "default";              /* in zephyr/boards/microchip/sam/sam_e54_xpro/sam_e54_xpro.dts:191 */
			status = "okay";                        /* in zephyr/boards/microchip/sam/sam_e54_xpro/sam_e54_xpro.dts:192 */
		};

		/* node '/soc/tcc@43001000' defined in zephyr/dts/arm/microchip/sam/sam_d5x_e5x/common/samd5xe5x_p.dtsi:43 */
		tcc4: tcc@43001000 {
			compatible = "microchip,tcc-g1";     /* in zephyr/dts/arm/microchip/sam/sam_d5x_e5x/common/samd5xe5x_p.dtsi:44 */
			reg = < 0x43001000 0x2000 >;         /* in zephyr/dts/arm/microchip/sam/sam_d5x_e5x/common/samd5xe5x_p.dtsi:45 */
			interrupts = < 0x68 0x0 >,
			             < 0x69 0x0 >,
			             < 0x6a 0x0 >;           /* in zephyr/dts/arm/microchip/sam/sam_d5x_e5x/common/samd5xe5x_p.dtsi:46 */
			clocks = < &mclkperiph 0x20413f41 >,
			         < &gclkperiph 0x1bffe631 >; /* in zephyr/dts/arm/microchip/sam/sam_d5x_e5x/common/samd5xe5x_p.dtsi:47 */
			clock-names = "mclk",
			              "gclk";                /* in zephyr/dts/arm/microchip/sam/sam_d5x_e5x/common/samd5xe5x_p.dtsi:49 */
			max-bit-width = < 0x10 >;            /* in zephyr/dts/arm/microchip/sam/sam_d5x_e5x/common/samd5xe5x_p.dtsi:50 */
			channels = < 0x2 >;                  /* in zephyr/dts/arm/microchip/sam/sam_d5x_e5x/common/samd5xe5x_p.dtsi:51 */
		};
	};

	/* node '/chosen' defined in zephyr/dts/common/skeleton.dtsi:13 */
	chosen {
		zephyr,console = &sercom2;                /* in zephyr/boards/microchip/sam/sam_e54_xpro/sam_e54_xpro.dts:18 */
		zephyr,shell-uart = &sercom2;             /* in zephyr/boards/microchip/sam/sam_e54_xpro/sam_e54_xpro.dts:19 */
		zephyr,sram = &sram0;                     /* in zephyr/boards/microchip/sam/sam_e54_xpro/sam_e54_xpro.dts:20 */
		zephyr,flash = &flash0;                   /* in zephyr/boards/microchip/sam/sam_e54_xpro/sam_e54_xpro.dts:21 */
		zephyr,code-partition = &slot0_partition; /* in zephyr/boards/microchip/sam/sam_e54_xpro/sam_e54_xpro.dts:22 */
		zephyr,flash-controller = &nvmctrl;       /* in zephyr/boards/microchip/sam/sam_e54_xpro/sam_e54_xpro.dts:23 */
	};

	/* node '/aliases' defined in zephyr/dts/common/skeleton.dtsi:15 */
	aliases {
		led0 = &led0;         /* in zephyr/boards/microchip/sam/sam_e54_xpro/sam_e54_xpro.dts:27 */
		pwm-led0 = &pwm_led0; /* in zephyr/boards/microchip/sam/sam_e54_xpro/sam_e54_xpro.dts:28 */
		sw0 = &button0;       /* in zephyr/boards/microchip/sam/sam_e54_xpro/sam_e54_xpro.dts:29 */
	};

	/* node '/cpus' defined in zephyr/dts/arm/microchip/sam/sam_d5x_e5x/common/samd5xe5x.dtsi:13 */
	cpus {
		#address-cells = < 0x1 >; /* in zephyr/dts/arm/microchip/sam/sam_d5x_e5x/common/samd5xe5x.dtsi:14 */
		#size-cells = < 0x0 >;    /* in zephyr/dts/arm/microchip/sam/sam_d5x_e5x/common/samd5xe5x.dtsi:15 */

		/* node '/cpus/cpu@0' defined in zephyr/dts/arm/microchip/sam/sam_d5x_e5x/common/samd5xe5x.dtsi:17 */
		cpu0: cpu@0 {
			device_type = "cpu";             /* in zephyr/dts/arm/microchip/sam/sam_d5x_e5x/common/samd5xe5x.dtsi:18 */
			compatible = "arm,cortex-m4f";   /* in zephyr/dts/arm/microchip/sam/sam_d5x_e5x/common/samd5xe5x.dtsi:19 */
			reg = < 0x0 >;                   /* in zephyr/dts/arm/microchip/sam/sam_d5x_e5x/common/samd5xe5x.dtsi:20 */
			#address-cells = < 0x1 >;        /* in zephyr/dts/arm/microchip/sam/sam_d5x_e5x/common/samd5xe5x.dtsi:21 */
			#size-cells = < 0x1 >;           /* in zephyr/dts/arm/microchip/sam/sam_d5x_e5x/common/samd5xe5x.dtsi:22 */
			clock-frequency = < 0x7270e00 >; /* in zephyr/boards/microchip/sam/sam_e54_xpro/sam_e54_xpro.dts:87 */

			/* node '/cpus/cpu@0/mpu@e000ed90' defined in zephyr/dts/arm/microchip/sam/sam_d5x_e5x/common/samd5xe5x.dtsi:24 */
			mpu: mpu@e000ed90 {
				compatible = "arm,armv7m-mpu"; /* in zephyr/dts/arm/microchip/sam/sam_d5x_e5x/common/samd5xe5x.dtsi:25 */
				reg = < 0xe000ed90 0x2c >;     /* in zephyr/dts/arm/microchip/sam/sam_d5x_e5x/common/samd5xe5x.dtsi:26 */
			};
		};
	};

	/* node '/leds' defined in zephyr/boards/microchip/sam/sam_e54_xpro/sam_e54_xpro.dts:32 */
	leds {
		compatible = "gpio-leds"; /* in zephyr/boards/microchip/sam/sam_e54_xpro/sam_e54_xpro.dts:33 */

		/* node '/leds/led_0' defined in zephyr/boards/microchip/sam/sam_e54_xpro/sam_e54_xpro.dts:35 */
		led0: led_0 {
			gpios = < &portc 0x12 0x1 >; /* in zephyr/boards/microchip/sam/sam_e54_xpro/sam_e54_xpro.dts:36 */
			label = "Yellow LED";        /* in zephyr/boards/microchip/sam/sam_e54_xpro/sam_e54_xpro.dts:37 */
		};
	};

	/* node '/pwmleds' defined in zephyr/boards/microchip/sam/sam_e54_xpro/sam_e54_xpro.dts:41 */
	pwmleds {
		compatible = "pwm-leds"; /* in zephyr/boards/microchip/sam/sam_e54_xpro/sam_e54_xpro.dts:42 */

		/* node '/pwmleds/pwm_led_0' defined in zephyr/boards/microchip/sam/sam_e54_xpro/sam_e54_xpro.dts:44 */
		pwm_led0: pwm_led_0 {
			status = "okay";                    /* in zephyr/boards/microchip/sam/sam_e54_xpro/sam_e54_xpro.dts:45 */
			pwms = < &tcc0 0x2 0x1312d00 0x0 >; /* in zephyr/boards/microchip/sam/sam_e54_xpro/sam_e54_xpro.dts:46 */
		};
	};

	/* node '/buttons' defined in zephyr/boards/microchip/sam/sam_e54_xpro/sam_e54_xpro.dts:50 */
	buttons {
		compatible = "gpio-keys"; /* in zephyr/boards/microchip/sam/sam_e54_xpro/sam_e54_xpro.dts:51 */

		/* node '/buttons/button_0' defined in zephyr/boards/microchip/sam/sam_e54_xpro/sam_e54_xpro.dts:53 */
		button0: button_0 {
			gpios = < &portb 0x1f 0x11 >; /* in zephyr/boards/microchip/sam/sam_e54_xpro/sam_e54_xpro.dts:54 */
			label = "SW0";                /* in zephyr/boards/microchip/sam/sam_e54_xpro/sam_e54_xpro.dts:55 */
			zephyr,code = < 0xb >;        /* in zephyr/boards/microchip/sam/sam_e54_xpro/sam_e54_xpro.dts:56 */
		};
	};
};
